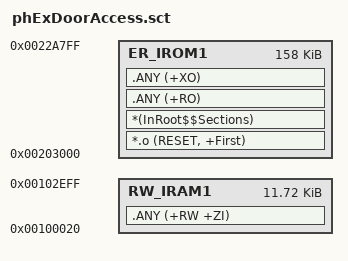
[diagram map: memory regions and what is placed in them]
; *************************************************************
; *** Scatter-Loading Description File generated by uVision ***
; *************************************************************

LR_IROM1 0x00203000 0x00027800  {    ; load region size_region
  ER_IROM1 0x00203000 0x00027800  {  ; load address = execution address
   *.o (RESET, +First)
   *(InRoot$$Sections)
   .ANY (+RO)
   .ANY (+XO)
  }
  RW_IRAM1 0x00100020 0x00002EE0  {  ; RW data
   .ANY (+RW +ZI)
  }
}

